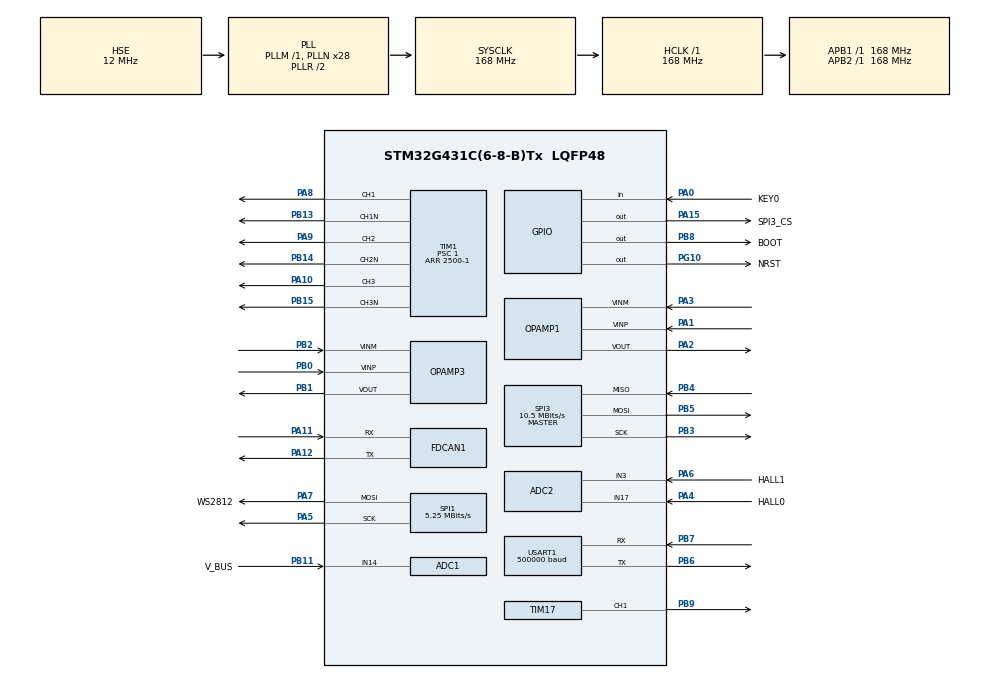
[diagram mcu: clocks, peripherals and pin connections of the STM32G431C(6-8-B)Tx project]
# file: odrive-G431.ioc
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ADC1.Channel-3\#ChannelRegularConversion=ADC_CHANNEL_3
ADC1.Channel-4\#ChannelRegularConversion=ADC_CHANNEL_12
ADC1.Channel-5\#ChannelRegularConversion=ADC_CHANNEL_14
ADC1.ClockPrescaler=ADC_CLOCK_SYNC_PCLK_DIV4
ADC1.ContinuousConvMode=DISABLE
ADC1.DMAContinuousRequests=ENABLE
ADC1.EOCSelection=ADC_EOC_SEQ_CONV
ADC1.EnableAnalogWatchDog1=false
ADC1.EnableInjectedConversion=DISABLE
ADC1.EnableRegularConversion=ENABLE
ADC1.NbrOfConversion=3
ADC1.NbrOfConversionFlag=1
ADC1.OffsetNumber-3\#ChannelRegularConversion=ADC_OFFSET_NONE
ADC1.OffsetNumber-4\#ChannelRegularConversion=ADC_OFFSET_NONE
ADC1.OffsetNumber-5\#ChannelRegularConversion=ADC_OFFSET_NONE
ADC1.Rank-3\#ChannelRegularConversion=1
ADC1.Rank-4\#ChannelRegularConversion=2
ADC1.Rank-5\#ChannelRegularConversion=3
ADC1.SamplingTime-3\#ChannelRegularConversion=ADC_SAMPLETIME_24CYCLES_5
ADC1.SamplingTime-4\#ChannelRegularConversion=ADC_SAMPLETIME_24CYCLES_5
ADC1.SamplingTime-5\#ChannelRegularConversion=ADC_SAMPLETIME_24CYCLES_5
ADC1.master=1
ADC2.Channel-0\#ChannelRegularConversion=ADC_CHANNEL_3
ADC2.Channel-1\#ChannelRegularConversion=ADC_CHANNEL_17
ADC2.DMAContinuousRequests=ENABLE
ADC2.EOCSelection=ADC_EOC_SEQ_CONV
ADC2.NbrOfConversion=2
ADC2.NbrOfConversionFlag=1
ADC2.OffsetNumber-0\#ChannelRegularConversion=ADC_OFFSET_NONE
ADC2.OffsetNumber-1\#ChannelRegularConversion=ADC_OFFSET_NONE
ADC2.Rank-0\#ChannelRegularConversion=1
ADC2.Rank-1\#ChannelRegularConversion=2
ADC2.SamplingTime-0\#ChannelRegularConversion=ADC_SAMPLETIME_24CYCLES_5
ADC2.SamplingTime-1\#ChannelRegularConversion=ADC_SAMPLETIME_24CYCLES_5
Dma.ADC1.0.Direction=DMA_PERIPH_TO_MEMORY
Dma.ADC1.0.EventEnable=DISABLE
Dma.ADC1.0.Instance=DMA1_Channel2
Dma.ADC1.0.MemDataAlignment=DMA_MDATAALIGN_WORD
Dma.ADC1.0.MemInc=DMA_MINC_ENABLE
Dma.ADC1.0.Mode=DMA_CIRCULAR
Dma.ADC1.0.PeriphDataAlignment=DMA_PDATAALIGN_WORD
Dma.ADC1.0.PeriphInc=DMA_PINC_DISABLE
Dma.ADC1.0.Polarity=HAL_DMAMUX_REQ_GEN_RISING
Dma.ADC1.0.Priority=DMA_PRIORITY_VERY_HIGH
Dma.ADC1.0.RequestNumber=1
Dma.ADC1.0.SignalID=NONE
Dma.ADC1.0.SyncEnable=DISABLE
Dma.ADC1.0.SyncPolarity=HAL_DMAMUX_SYNC_NO_EVENT
Dma.ADC1.0.SyncRequestNumber=1
Dma.ADC1.0.SyncSignalID=NONE
Dma.ADC2.4.Direction=DMA_PERIPH_TO_MEMORY
Dma.ADC2.4.EventEnable=DISABLE
Dma.ADC2.4.Instance=DMA2_Channel1
Dma.ADC2.4.MemDataAlignment=DMA_MDATAALIGN_WORD
Dma.ADC2.4.MemInc=DMA_MINC_ENABLE
Dma.ADC2.4.Mode=DMA_CIRCULAR
Dma.ADC2.4.PeriphDataAlignment=DMA_PDATAALIGN_WORD
Dma.ADC2.4.PeriphInc=DMA_PINC_DISABLE
Dma.ADC2.4.Polarity=HAL_DMAMUX_REQ_GEN_RISING
Dma.ADC2.4.Priority=DMA_PRIORITY_HIGH
Dma.ADC2.4.RequestNumber=1
Dma.ADC2.4.SignalID=NONE
Dma.ADC2.4.SyncEnable=DISABLE
Dma.ADC2.4.SyncPolarity=HAL_DMAMUX_SYNC_NO_EVENT
Dma.ADC2.4.SyncRequestNumber=1
Dma.ADC2.4.SyncSignalID=NONE
Dma.Request0=ADC1
Dma.Request1=USART1_TX
Dma.Request2=USART1_RX
Dma.Request3=SPI1_TX
Dma.Request4=ADC2
Dma.SPI1_TX.3.Direction=DMA_MEMORY_TO_PERIPH
Dma.SPI1_TX.3.EventEnable=DISABLE
Dma.SPI1_TX.3.Instance=DMA1_Channel3
Dma.SPI1_TX.3.MemDataAlignment=DMA_MDATAALIGN_BYTE
Dma.SPI1_TX.3.MemInc=DMA_MINC_ENABLE
Dma.SPI1_TX.3.Mode=DMA_NORMAL
Dma.SPI1_TX.3.PeriphDataAlignment=DMA_PDATAALIGN_BYTE
Dma.SPI1_TX.3.PeriphInc=DMA_PINC_DISABLE
Dma.SPI1_TX.3.Polarity=HAL_DMAMUX_REQ_GEN_RISING
Dma.SPI1_TX.3.Priority=DMA_PRIORITY_VERY_HIGH
Dma.SPI1_TX.3.RequestNumber=1
Dma.SPI1_TX.3.SignalID=NONE
Dma.SPI1_TX.3.SyncEnable=DISABLE
Dma.SPI1_TX.3.SyncPolarity=HAL_DMAMUX_SYNC_NO_EVENT
Dma.SPI1_TX.3.SyncRequestNumber=1
Dma.SPI1_TX.3.SyncSignalID=NONE
Dma.USART1_RX.2.Direction=DMA_PERIPH_TO_MEMORY
Dma.USART1_RX.2.EventEnable=DISABLE
Dma.USART1_RX.2.Instance=DMA2_Channel2
Dma.USART1_RX.2.MemDataAlignment=DMA_MDATAALIGN_BYTE
Dma.USART1_RX.2.MemInc=DMA_MINC_ENABLE
Dma.USART1_RX.2.Mode=DMA_CIRCULAR
Dma.USART1_RX.2.PeriphDataAlignment=DMA_PDATAALIGN_BYTE
Dma.USART1_RX.2.PeriphInc=DMA_PINC_DISABLE
Dma.USART1_RX.2.Polarity=HAL_DMAMUX_REQ_GEN_RISING
Dma.USART1_RX.2.Priority=DMA_PRIORITY_VERY_HIGH
Dma.USART1_RX.2.RequestNumber=1
Dma.USART1_RX.2.SignalID=NONE
Dma.USART1_RX.2.SyncEnable=DISABLE
Dma.USART1_RX.2.SyncPolarity=HAL_DMAMUX_SYNC_NO_EVENT
Dma.USART1_RX.2.SyncRequestNumber=1
Dma.USART1_RX.2.SyncSignalID=NONE
Dma.USART1_TX.1.Direction=DMA_MEMORY_TO_PERIPH
Dma.USART1_TX.1.EventEnable=DISABLE
Dma.USART1_TX.1.Instance=DMA1_Channel1
Dma.USART1_TX.1.MemDataAlignment=DMA_MDATAALIGN_BYTE
Dma.USART1_TX.1.MemInc=DMA_MINC_ENABLE
Dma.USART1_TX.1.Mode=DMA_NORMAL
Dma.USART1_TX.1.PeriphDataAlignment=DMA_PDATAALIGN_BYTE
Dma.USART1_TX.1.PeriphInc=DMA_PINC_DISABLE
Dma.USART1_TX.1.Polarity=HAL_DMAMUX_REQ_GEN_RISING
Dma.USART1_TX.1.Priority=DMA_PRIORITY_VERY_HIGH
Dma.USART1_TX.1.RequestNumber=1
Dma.USART1_TX.1.SignalID=NONE
Dma.USART1_TX.1.SyncEnable=DISABLE
Dma.USART1_TX.1.SyncPolarity=HAL_DMAMUX_SYNC_NO_EVENT
Dma.USART1_TX.1.SyncRequestNumber=1
Dma.USART1_TX.1.SyncSignalID=NONE
FDCAN1.AutoRetransmission=ENABLE
FDCAN1.CalculateBaudRateNominal=1000000
FDCAN1.CalculateTimeBitNominal=1000
FDCAN1.CalculateTimeQuantumNominal=47.61904761904762
FDCAN1.ClockDivider=FDCAN_CLOCK_DIV2
FDCAN1.DataPrescaler=5
FDCAN1.DataTimeSeg1=8
FDCAN1.DataTimeSeg2=8
FDCAN1.ExtFiltersNbr=0
FDCAN1.FrameFormat=FDCAN_FRAME_FD_BRS
FDCAN1.NominalPrescaler=4
FDCAN1.NominalTimeSeg1=8
FDCAN1.NominalTimeSeg2=12
FDCAN1.ProtocolException=DISABLE
FDCAN1.StdFiltersNbr=0
FDCAN1.TransmitPause=DISABLE
Mcu.Family=STM32G4
Mcu.Name=STM32G431C(6-8-B)Tx
Mcu.Package=LQFP48
NVIC.DMA1_Channel1_IRQn=true\:0\:0\:false\:false\:true\:false\:true\:true
NVIC.DMA1_Channel2_IRQn=true\:0\:0\:false\:false\:true\:false\:true\:true
NVIC.DMA1_Channel3_IRQn=true\:0\:0\:false\:false\:true\:false\:true\:true
NVIC.DMA2_Channel1_IRQn=true\:0\:0\:false\:false\:true\:false\:true\:true
NVIC.DMA2_Channel2_IRQn=true\:15\:0\:true\:false\:true\:false\:true\:true
NVIC.FDCAN1_IT0_IRQn=true\:0\:0\:true\:false\:true\:true\:true\:true
NVIC.PriorityGroup=NVIC_PRIORITYGROUP_4
NVIC.SPI3_IRQn=true\:0\:0\:false\:false\:true\:true\:true\:true
NVIC.TIM1_CC_IRQn=true\:0\:0\:true\:false\:true\:true\:true\:true
NVIC.TIM6_DAC_IRQn=true\:0\:0\:false\:false\:true\:true\:true\:true
NVIC.USART1_IRQn=true\:0\:0\:false\:false\:true\:true\:true\:true
PA0.GPIO_Label=KEY0
PA0.GPIO_PuPd=GPIO_PULLUP
PA0.Signal=GPIO_Input
PA1.GPIO_PuPd=GPIO_NOPULL
PA1.Mode=Standalone
PA1.Signal=OPAMP1_VINP
PA10.GPIO_ModeDefaultPP=GPIO_MODE_AF_PP
PA10.GPIO_PuPd=GPIO_PULLDOWN
PA10.GPIO_Speed=GPIO_SPEED_FREQ_LOW
PA10.Signal=S_TIM1_CH3
PA11.GPIO_PuPd=GPIO_PULLDOWN
PA11.GPIO_Speed=GPIO_SPEED_FREQ_MEDIUM
PA11.Mode=FDCAN_Activate
PA11.Signal=FDCAN1_RX
PA12.GPIO_PuPd=GPIO_PULLDOWN
PA12.GPIO_Speed=GPIO_SPEED_FREQ_MEDIUM
PA12.Mode=FDCAN_Activate
PA12.Signal=FDCAN1_TX
PA13.Mode=Serial_Wire
PA13.Signal=SYS_JTMS-SWDIO
PA14.Mode=Serial_Wire
PA14.Signal=SYS_JTCK-SWCLK
PA15.GPIO_Label=SPI3_CS
PA15.GPIO_PuPd=GPIO_PULLUP
PA15.GPIO_Speed=GPIO_SPEED_FREQ_MEDIUM
PA15.PinState=GPIO_PIN_SET
PA15.Signal=GPIO_Output
PA2.GPIO_PuPd=GPIO_NOPULL
PA2.Signal=SharedAnalog_PA2
PA3.GPIO_PuPd=GPIO_NOPULL
PA3.Mode=Standalone
PA3.Signal=OPAMP1_VINM
PA4.GPIO_Label=HALL0
PA4.Mode=IN17-Single-Ended
PA4.Signal=ADC2_IN17
PA5.GPIO_Mode=GPIO_MODE_AF_PP
PA5.GPIO_PuPd=GPIO_PULLDOWN
PA5.GPIO_Speed=GPIO_SPEED_FREQ_VERY_HIGH
PA5.Mode=TX_Only_Simplex_Unidirect_Master
PA5.Signal=SPI1_SCK
PA6.GPIO_Label=HALL1
PA6.Mode=IN3-Single-Ended
PA6.Signal=ADC2_IN3
PA7.GPIO_Label=WS2812
PA7.GPIO_Mode=GPIO_MODE_AF_PP
PA7.GPIO_PuPd=GPIO_PULLDOWN
PA7.GPIO_Speed=GPIO_SPEED_FREQ_VERY_HIGH
PA7.Mode=TX_Only_Simplex_Unidirect_Master
PA7.Signal=SPI1_MOSI
PA8.GPIO_ModeDefaultPP=GPIO_MODE_AF_PP
PA8.GPIO_PuPd=GPIO_PULLDOWN
PA8.GPIO_Speed=GPIO_SPEED_FREQ_LOW
PA8.Signal=S_TIM1_CH1
PA9.GPIO_ModeDefaultPP=GPIO_MODE_AF_PP
PA9.GPIO_PuPd=GPIO_PULLDOWN
PA9.GPIO_Speed=GPIO_SPEED_FREQ_LOW
PA9.Signal=S_TIM1_CH2
PB0.GPIO_PuPd=GPIO_NOPULL
PB0.Mode=Standalone
PB0.Signal=OPAMP3_VINP
PB1.GPIO_PuPd=GPIO_NOPULL
PB1.Signal=SharedAnalog_PB1
PB11.GPIO_Label=V_BUS
PB11.Mode=IN14-Single-Ended
PB11.Signal=ADC1_IN14
PB13.GPIO_ModeDefaultPP=GPIO_MODE_AF_PP
PB13.GPIO_PuPd=GPIO_PULLDOWN
PB13.GPIO_Speed=GPIO_SPEED_FREQ_LOW
PB13.Mode=PWM Generation1 CH1 CH1N
PB13.Signal=TIM1_CH1N
PB14.GPIO_ModeDefaultPP=GPIO_MODE_AF_PP
PB14.GPIO_PuPd=GPIO_PULLDOWN
PB14.GPIO_Speed=GPIO_SPEED_FREQ_LOW
PB14.Mode=PWM Generation2 CH2 CH2N
PB14.Signal=TIM1_CH2N
PB15.GPIO_ModeDefaultPP=GPIO_MODE_AF_PP
PB15.GPIO_PuPd=GPIO_PULLDOWN
PB15.GPIO_Speed=GPIO_SPEED_FREQ_LOW
PB15.Mode=PWM Generation3 CH3 CH3N
PB15.Signal=TIM1_CH3N
PB2.GPIO_PuPd=GPIO_NOPULL
PB2.Mode=Standalone
PB2.Signal=OPAMP3_VINM
PB3.Mode=Full_Duplex_Master
PB3.Signal=SPI3_SCK
PB4.Mode=Full_Duplex_Master
PB4.Signal=SPI3_MISO
PB5.Mode=Full_Duplex_Master
PB5.Signal=SPI3_MOSI
PB6.Mode=Asynchronous
PB6.Signal=USART1_TX
PB7.Mode=Asynchronous
PB7.Signal=USART1_RX
PB8-BOOT0.GPIO_Label=BOOT
PB8-BOOT0.GPIO_PuPd=GPIO_PULLDOWN
PB8-BOOT0.Signal=GPIO_Output
PB9.GPIO_Speed=GPIO_SPEED_FREQ_LOW
PB9.Signal=S_TIM17_CH1
PF0-OSC_IN.Mode=HSE-External-Clock-Source
PF0-OSC_IN.Signal=RCC_OSC_IN
PG10-NRST.GPIO_Label=NRST
PG10-NRST.GPIO_PuPd=GPIO_PULLUP
PG10-NRST.Signal=GPIO_Output
ProjectManager.HeapSize=0x400
ProjectManager.StackSize=0x800
ProjectManager.TargetToolchain=CMake
RCC.ADC12Freq_Value=168000000
RCC.AHBFreq_Value=168000000
RCC.APB1Freq_Value=168000000
RCC.APB1TimFreq_Value=168000000
RCC.APB2Freq_Value=168000000
RCC.APB2TimFreq_Value=168000000
RCC.CortexFreq_Value=168000000
RCC.EXTERNAL_CLOCK_VALUE=12288000
RCC.HCLKFreq_Value=168000000
RCC.HSE_VALUE=12000000
RCC.HSI48_VALUE=48000000
RCC.HSI_VALUE=16000000
RCC.LSE_VALUE=32768
RCC.PLLN=28
RCC.PLLSourceVirtual=RCC_PLLSOURCE_HSE
RCC.SYSCLKFreq_VALUE=168000000
RCC.SYSCLKSource=RCC_SYSCLKSOURCE_PLLCLK
RCC.USART3CLockSelection=RCC_USART3CLKSOURCE_SYSCLK
RCC.USBFreq_Value=168000000
RCC.VCOOutputFreq_Value=336000000
SH.S_TIM17_CH1.0=TIM17_CH1,PWM Generation1 CH1
SH.S_TIM1_CH1.0=TIM1_CH1,PWM Generation1 CH1 CH1N
SH.S_TIM1_CH2.0=TIM1_CH2,PWM Generation2 CH2 CH2N
SH.S_TIM1_CH3.0=TIM1_CH3,PWM Generation3 CH3 CH3N
SH.SharedAnalog_PA2.0=OPAMP1_VOUT,Standalone
SH.SharedAnalog_PA2.1=ADC1_IN3,IN3-Single-Ended
SH.SharedAnalog_PB1.0=OPAMP3_VOUT,Standalone
SH.SharedAnalog_PB1.1=ADC1_IN12,IN12-Single-Ended
SPI1.BaudRatePrescaler=SPI_BAUDRATEPRESCALER_32
SPI1.CLKPhase=SPI_PHASE_2EDGE
SPI1.CLKPolarity=SPI_POLARITY_HIGH
SPI1.CalculateBaudRate=5.25 MBits/s
SPI1.DataSize=SPI_DATASIZE_8BIT
SPI1.Direction=SPI_DIRECTION_2LINES
SPI1.Mode=SPI_MODE_MASTER
SPI1.VirtualType=VM_MASTER
SPI3.BaudRatePrescaler=SPI_BAUDRATEPRESCALER_16
SPI3.CLKPhase=SPI_PHASE_2EDGE
SPI3.CalculateBaudRate=10.5 MBits/s
SPI3.DataSize=SPI_DATASIZE_16BIT
SPI3.Direction=SPI_DIRECTION_2LINES
SPI3.Mode=SPI_MODE_MASTER
SPI3.VirtualType=VM_MASTER
TIM1.AutoReloadPreload=TIM_AUTORELOAD_PRELOAD_ENABLE
TIM1.Channel-PWM\ Generation1\ CH1\ CH1N=TIM_CHANNEL_1
TIM1.Channel-PWM\ Generation2\ CH2\ CH2N=TIM_CHANNEL_2
TIM1.Channel-PWM\ Generation3\ CH3\ CH3N=TIM_CHANNEL_3
TIM1.Channel-PWM\ Generation4\ No\ Output=TIM_CHANNEL_4
TIM1.CounterMode=TIM_COUNTERMODE_CENTERALIGNED2
TIM1.DeadTime=0
TIM1.DeadTimePreload=ENABLE
TIM1.Dithering=Disable
TIM1.OffStateIDLEMode=TIM_OSSI_ENABLE
TIM1.OffStateRunMode=TIM_OSSR_ENABLE
TIM1.PeriodNoDither=2500-1
TIM1.Prescaler=1
TIM1.RepetitionCounter=0
TIM1.TIM_MasterOutputTrigger=TIM_TRGO_OC4REF
TIM1.TIM_MasterOutputTrigger2=TIM_TRGO2_OC4REF
TIM1.TIM_MasterSlaveMode=TIM_MASTERSLAVEMODE_DISABLE
TIM17.Channel=TIM_CHANNEL_1
TIM17.PeriodNoDither=1024-1
TIM17.Prescaler=16-1
TIM6.AutoReloadPreload=TIM_AUTORELOAD_PRELOAD_ENABLE
TIM6.PeriodNoDither=5000-1
TIM6.Prescaler=17-1
USART1.BaudRate=500000
USART1.VirtualMode-Asynchronous=VM_ASYNC
VP_SYS_VS_DBSignals.Mode=DisableDeadBatterySignals
VP_TIM17_VS_ClockSourceINT.Mode=Enable_Timer
VP_TIM1_VS_ClockSourceINT.Mode=Internal
VP_TIM1_VS_no_output4.Mode=PWM Generation4 No Output
VP_TIM6_VS_ClockSourceINT.Mode=Enable_Timer
board=custom

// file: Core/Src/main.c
/* USER CODE BEGIN Header */
/**
 ******************************************************************************
 * @file           : main.c
 * @brief          : Main program body
 ******************************************************************************
 * @attention
 *
 * Copyright (c) 2023 STMicroelectronics.
 * All rights reserved.
 *
 * This software is licensed under terms that can be found in the LICENSE file
 * in the root directory of this software component.
 * If no LICENSE file comes with this software, it is provided AS-IS.
 *
 ******************************************************************************
 */
/* USER CODE END Header */
#include "main.h"

#include "adc.h"
#include "dma.h"
#include "fdcan.h"
#include "gpio.h"
#include "opamp.h"
#include "spi.h"
#include "tim.h"
#include "usart.h"

/* USER CODE BEGIN Includes */
#include "app.h"
/* USER CODE END Includes */

void SystemClock_Config(void);

int main(void) {

  /* MCU Configuration--------------------------------------------------------*/

  /* Reset of all peripherals, Initializes the Flash interface and the Systick.
   */
  HAL_Init();

  /* Configure the system clock */
  SystemClock_Config();

  /* Initialize all configured peripherals */
  MX_GPIO_Init();
  MX_DMA_Init();
  MX_ADC1_Init();
  MX_FDCAN1_Init();
  MX_TIM1_Init();
  MX_USART1_UART_Init();
  MX_OPAMP1_Init();
  MX_OPAMP3_Init();
  MX_SPI1_Init();
  MX_SPI3_Init();
  MX_TIM6_Init();
  MX_ADC2_Init();
  MX_TIM17_Init();
  /* USER CODE BEGIN 2 */
  AppInit();
  /* USER CODE END 2 */

  /* Infinite loop */
  while (1) {

    /* USER CODE BEGIN 3 */

    AppRunning();
  }
  /* USER CODE END 3 */
}

void SystemClock_Config(void) {
  RCC_OscInitTypeDef RCC_OscInitStruct = {0};
  RCC_ClkInitTypeDef RCC_ClkInitStruct = {0};

  /** Configure the main internal regulator output voltage
   */
  HAL_PWREx_ControlVoltageScaling(PWR_REGULATOR_VOLTAGE_SCALE1_BOOST);

  /** Initializes the RCC Oscillators according to the specified parameters
   * in the RCC_OscInitTypeDef structure.
   */
  RCC_OscInitStruct.OscillatorType = RCC_OSCILLATORTYPE_HSE;
  RCC_OscInitStruct.HSEState = RCC_HSE_BYPASS;
  RCC_OscInitStruct.PLL.PLLState = RCC_PLL_ON;
  RCC_OscInitStruct.PLL.PLLSource = RCC_PLLSOURCE_HSE;
  RCC_OscInitStruct.PLL.PLLM = RCC_PLLM_DIV1;
  RCC_OscInitStruct.PLL.PLLN = 28;
  RCC_OscInitStruct.PLL.PLLP = RCC_PLLP_DIV2;
  RCC_OscInitStruct.PLL.PLLQ = RCC_PLLQ_DIV2;
  RCC_OscInitStruct.PLL.PLLR = RCC_PLLR_DIV2;
  if (HAL_RCC_OscConfig(&RCC_OscInitStruct) != HAL_OK) {
    Error_Handler();
  }

  /** Initializes the CPU, AHB and APB buses clocks
   */
  RCC_ClkInitStruct.ClockType = RCC_CLOCKTYPE_HCLK | RCC_CLOCKTYPE_SYSCLK |
                                RCC_CLOCKTYPE_PCLK1 | RCC_CLOCKTYPE_PCLK2;
  RCC_ClkInitStruct.SYSCLKSource = RCC_SYSCLKSOURCE_PLLCLK;
  RCC_ClkInitStruct.AHBCLKDivider = RCC_SYSCLK_DIV1;
  RCC_ClkInitStruct.APB1CLKDivider = RCC_HCLK_DIV1;
  RCC_ClkInitStruct.APB2CLKDivider = RCC_HCLK_DIV1;

  if (HAL_RCC_ClockConfig(&RCC_ClkInitStruct, FLASH_LATENCY_4) != HAL_OK) {
    Error_Handler();
  }
}

void Error_Handler(void) {
  __disable_irq();
  while (1) {
  }
}

#ifdef USE_FULL_ASSERT
/**
 * @brief  Reports the name of the source file and the source line number
 *         where the assert_param error has occurred.
 * @param  file: pointer to the source file name
 * @param  line: assert_param error line source number
 * @retval None
 */
void assert_failed(uint8_t* file, uint32_t line) {
  /* USER CODE BEGIN 6 */
  /* User can add his own implementation to report the file name and line
     number, ex: printf("Wrong parameters value: file %s on line %d\r\n", file,
     line) */
  /* USER CODE END 6 */
}
#endif /* USE_FULL_ASSERT */
